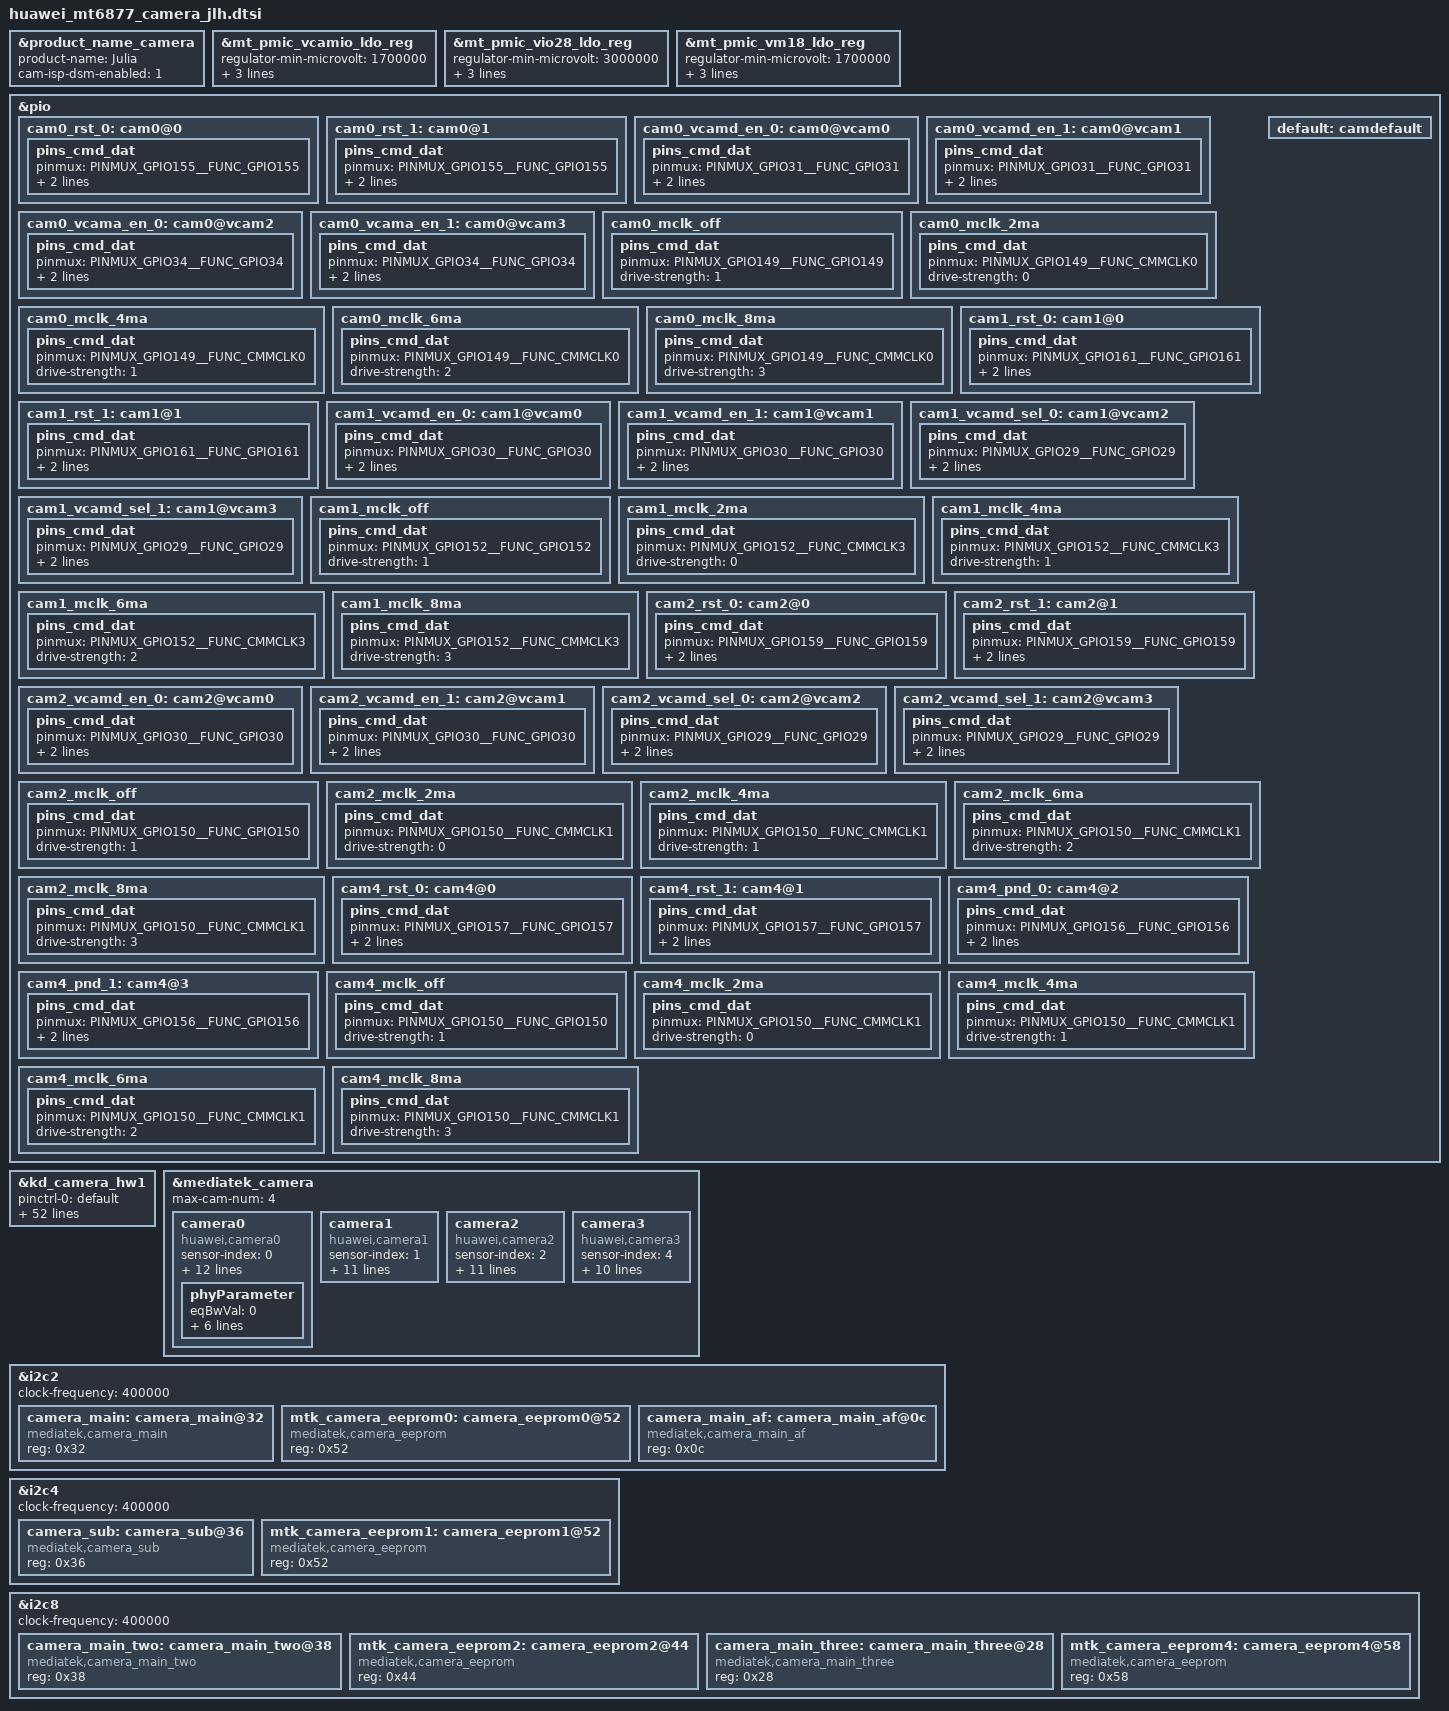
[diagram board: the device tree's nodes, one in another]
/*
 * Copyright (c) 2020 MediaTek Inc.
 *
 * This program is free software; you can redistribute it and/or modify
 * it under the terms of the GNU General Public License version 2 as
 * published by the Free Software Foundation.
 *
 * This program is distributed in the hope that it will be useful,
 * but WITHOUT ANY WARRANTY; without even the implied warranty of
 * MERCHANTABILITY or FITNESS FOR A PARTICULAR PURPOSE.  See the
 * GNU General Public License for more details.
 */

&product_name_camera {
	product-name = "Julia";
	cam-isp-dsm-enabled = <1>;
};

&mt_pmic_vcamio_ldo_reg {
	regulator-min-microvolt = <1700000>;
	regulator-max-microvolt = <1900000>;
	regulator-default-on = <2>; /* 0:skip, 1: off, 2:on */
	regulator-boot-on;
};
&mt_pmic_vio28_ldo_reg {
	regulator-min-microvolt = <3000000>;
	regulator-max-microvolt = <3000000>;
	regulator-default-on = <2>; /* 0:skip, 1: off, 2:on */
	regulator-boot-on;
};
&mt_pmic_vm18_ldo_reg {
	regulator-min-microvolt = <1700000>;
	regulator-max-microvolt = <1900000>;
	regulator-default-on = <2>; /* 0:skip, 1: off, 2:on */
	regulator-boot-on;
};
/* CAMERA GPIO standardization */
&pio {
	/* Main Cam: cam0 GPIOs begin */
	cam0_rst_0: cam0@0 {
		pins_cmd_dat {
			pinmux = <PINMUX_GPIO155__FUNC_GPIO155>;
			slew-rate = <1>;
			output-low;
		};
	};
	cam0_rst_1: cam0@1 {
		pins_cmd_dat {
			pinmux = <PINMUX_GPIO155__FUNC_GPIO155>;
			slew-rate = <1>;
			output-high;
		};
	};

	cam0_vcamd_en_0: cam0@vcam0 {
		pins_cmd_dat {
			pinmux = <PINMUX_GPIO31__FUNC_GPIO31>;
			slew-rate = <1>;
			output-low;
		};
	};
	cam0_vcamd_en_1: cam0@vcam1 {
		pins_cmd_dat {
			pinmux = <PINMUX_GPIO31__FUNC_GPIO31>;
			slew-rate = <1>;
			output-high;
		};
	};

	cam0_vcama_en_0: cam0@vcam2 {
		pins_cmd_dat {
			pinmux = <PINMUX_GPIO34__FUNC_GPIO34>;
			slew-rate = <1>;
			output-low;
		};
	};
	cam0_vcama_en_1: cam0@vcam3 {
		pins_cmd_dat {
			pinmux = <PINMUX_GPIO34__FUNC_GPIO34>;
			slew-rate = <1>;
			output-high;
		};
	};

	cam0_mclk_off: cam0_mclk_off {
		pins_cmd_dat {
			pinmux = <PINMUX_GPIO149__FUNC_GPIO149>;
			drive-strength = <1>;
		};
	};
	cam0_mclk_2ma: cam0_mclk_2ma {
		pins_cmd_dat {
			pinmux = <PINMUX_GPIO149__FUNC_CMMCLK0>;
			drive-strength = <0>;
		};
	};
	cam0_mclk_4ma: cam0_mclk_4ma {
		pins_cmd_dat {
			pinmux = <PINMUX_GPIO149__FUNC_CMMCLK0>;
			drive-strength = <1>;
		};
	};
	cam0_mclk_6ma: cam0_mclk_6ma {
		pins_cmd_dat {
			pinmux = <PINMUX_GPIO149__FUNC_CMMCLK0>;
			drive-strength = <2>;
		};
	};
	cam0_mclk_8ma: cam0_mclk_8ma {
		pins_cmd_dat {
			pinmux = <PINMUX_GPIO149__FUNC_CMMCLK0>;
			drive-strength = <3>;
		};
	};
	/* Main Cam: cam0 GPIOs end */

	/* Sub(front) Cam: cam1 GPIOs begin */
	cam1_rst_0: cam1@0 {
		pins_cmd_dat {
			pinmux = <PINMUX_GPIO161__FUNC_GPIO161>;
			slew-rate = <1>;
			output-low;
		};
	};
	cam1_rst_1: cam1@1 {
		pins_cmd_dat {
			pinmux = <PINMUX_GPIO161__FUNC_GPIO161>;
			slew-rate = <1>;
			output-high;
		};
	};

	cam1_vcamd_en_0: cam1@vcam0 {
		pins_cmd_dat {
			pinmux = <PINMUX_GPIO30__FUNC_GPIO30>;
			slew-rate = <1>;
			output-low;
		};
	};
	cam1_vcamd_en_1: cam1@vcam1 {
		pins_cmd_dat {
			pinmux = <PINMUX_GPIO30__FUNC_GPIO30>;
			slew-rate = <1>;
			output-high;
		};
	};
	/* sel 0, output 1.1V */
	cam1_vcamd_sel_0: cam1@vcam2 {
		pins_cmd_dat {
			pinmux = <PINMUX_GPIO29__FUNC_GPIO29>;
			slew-rate = <1>;
			output-low;
		};
	};
	/* sel 1, output 1.2V */
	cam1_vcamd_sel_1: cam1@vcam3 {
		pins_cmd_dat {
			pinmux = <PINMUX_GPIO29__FUNC_GPIO29>;
			slew-rate = <0>;
			bias-pull-up = <MTK_PUPD_SET_R1R0_00>;
		};
	};

	cam1_mclk_off: cam1_mclk_off {
		pins_cmd_dat {
			pinmux = <PINMUX_GPIO152__FUNC_GPIO152>;
			drive-strength = <1>;
		};
	};
	cam1_mclk_2ma: cam1_mclk_2ma {
		pins_cmd_dat {
			pinmux = <PINMUX_GPIO152__FUNC_CMMCLK3>;
			drive-strength = <0>;
		};
	};
	cam1_mclk_4ma: cam1_mclk_4ma {
		pins_cmd_dat {
			pinmux = <PINMUX_GPIO152__FUNC_CMMCLK3>;
			drive-strength = <1>;
		};
	};
	cam1_mclk_6ma: cam1_mclk_6ma {
		pins_cmd_dat {
			pinmux = <PINMUX_GPIO152__FUNC_CMMCLK3>;
			drive-strength = <2>;
		};
	};
	cam1_mclk_8ma: cam1_mclk_8ma {
		pins_cmd_dat {
			pinmux = <PINMUX_GPIO152__FUNC_CMMCLK3>;
			drive-strength = <3>;
		};
	};
	/* Sub(front) Cam: cam1 GPIOs end */

	/* Main2(wide) Cam: cam2 GPIOs begin */
	cam2_rst_0: cam2@0 {
		pins_cmd_dat {
			pinmux = <PINMUX_GPIO159__FUNC_GPIO159>;
			slew-rate = <1>;
			output-low;
		};
	};
	cam2_rst_1: cam2@1 {
		pins_cmd_dat {
			pinmux = <PINMUX_GPIO159__FUNC_GPIO159>;
			slew-rate = <1>;
			output-high;
		};
	};

	cam2_vcamd_en_0: cam2@vcam0 {
		pins_cmd_dat {
			pinmux = <PINMUX_GPIO30__FUNC_GPIO30>;
			slew-rate = <1>;
			output-low;
		};
	};
	cam2_vcamd_en_1: cam2@vcam1 {
		pins_cmd_dat {
			pinmux = <PINMUX_GPIO30__FUNC_GPIO30>;
			slew-rate = <1>;
			output-high;
		};
	};
	/* sel 0, output 1.1V */
	cam2_vcamd_sel_0: cam2@vcam2 {
		pins_cmd_dat {
			pinmux = <PINMUX_GPIO29__FUNC_GPIO29>;
			slew-rate = <1>;
			output-low;
		};
	};
	/* sel 1, output 1.2V */
	cam2_vcamd_sel_1: cam2@vcam3 {
		pins_cmd_dat {
			pinmux = <PINMUX_GPIO29__FUNC_GPIO29>;
			slew-rate = <0>;
			bias-pull-up = <MTK_PUPD_SET_R1R0_00>;
		};
	};

	cam2_mclk_off: cam2_mclk_off {
		pins_cmd_dat {
			pinmux = <PINMUX_GPIO150__FUNC_GPIO150>;
			drive-strength = <1>;
		};
	};
	cam2_mclk_2ma: cam2_mclk_2ma {
		pins_cmd_dat {
			pinmux = <PINMUX_GPIO150__FUNC_CMMCLK1>;
			drive-strength = <0>;
		};
	};
	cam2_mclk_4ma: cam2_mclk_4ma {
		pins_cmd_dat {
			pinmux = <PINMUX_GPIO150__FUNC_CMMCLK1>;
			drive-strength = <1>;
		};
	};
	cam2_mclk_6ma: cam2_mclk_6ma {
		pins_cmd_dat {
			pinmux = <PINMUX_GPIO150__FUNC_CMMCLK1>;
			drive-strength = <2>;
		};
	};
	cam2_mclk_8ma: cam2_mclk_8ma {
		pins_cmd_dat {
			pinmux = <PINMUX_GPIO150__FUNC_CMMCLK1>;
			drive-strength = <3>;
		};
	};
	/* Main2(wide) Cam: cam2 GPIOs end */

	/* Main3(macro) Cam: cam4 GPIOs begin */
	cam4_rst_0: cam4@0 {
		pins_cmd_dat {
			pinmux = <PINMUX_GPIO157__FUNC_GPIO157>;
			slew-rate = <1>;
			output-low;
		};
	};
	cam4_rst_1: cam4@1 {
		pins_cmd_dat {
			pinmux = <PINMUX_GPIO157__FUNC_GPIO157>;
			slew-rate = <1>;
			output-high;
		};
	};

	cam4_pnd_0: cam4@2 {
		pins_cmd_dat {
			pinmux = <PINMUX_GPIO156__FUNC_GPIO156>;
			slew-rate = <1>;
			output-low;
		};
	};
	cam4_pnd_1: cam4@3 {
		pins_cmd_dat {
			pinmux = <PINMUX_GPIO156__FUNC_GPIO156>;
			slew-rate = <1>;
			output-high;
		};
	};

	cam4_mclk_off: cam4_mclk_off {
		pins_cmd_dat {
			pinmux = <PINMUX_GPIO150__FUNC_GPIO150>;
			drive-strength = <1>;
		};
	};
	cam4_mclk_2ma: cam4_mclk_2ma {
		pins_cmd_dat {
			pinmux = <PINMUX_GPIO150__FUNC_CMMCLK1>;
			drive-strength = <0>;
		};
	};
	cam4_mclk_4ma: cam4_mclk_4ma {
		pins_cmd_dat {
			pinmux = <PINMUX_GPIO150__FUNC_CMMCLK1>;
			drive-strength = <1>;
		};
	};
	cam4_mclk_6ma: cam4_mclk_6ma {
		pins_cmd_dat {
			pinmux = <PINMUX_GPIO150__FUNC_CMMCLK1>;
			drive-strength = <2>;
		};
	};
	cam4_mclk_8ma: cam4_mclk_8ma {
		pins_cmd_dat {
			pinmux = <PINMUX_GPIO150__FUNC_CMMCLK1>;
			drive-strength = <3>;
		};
	};
	/* Main3(macro) Cam: cam4 GPIOs end */

	default: camdefault {
	};
};

&kd_camera_hw1 {
	pinctrl-names = "default",
			/* Main Cam: Cam0 begin */
			"cam0_rst0", "cam0_rst1",
			"cam0_vcamd_en_0", "cam0_vcamd_en_1",
			"cam0_vcama_en_0", "cam0_vcama_en_1",
			"cam0_mclk_off",
			"cam0_mclk_2mA", "cam0_mclk_4mA",
			"cam0_mclk_6mA", "cam0_mclk_8mA",
			/* Main Cam: Cam0 end */

			/* Sub(front) Cam: Cam1 begin */
			"cam1_rst0", "cam1_rst1",
			"cam1_vcamd_en_0", "cam1_vcamd_en_1",
			"cam1_vcamd_sel_0", "cam1_vcamd_sel_1",
			"cam1_mclk_off",
			"cam1_mclk_2mA", "cam1_mclk_4mA",
			"cam1_mclk_6mA", "cam1_mclk_8mA",
			/* Sub(front) Cam: Cam1 end */

			/* Main2(wide) Cam: Cam2 begin */
			"cam2_rst0", "cam2_rst1",
			"cam2_vcamd_en_0", "cam2_vcamd_en_1",
			"cam2_vcamd_sel_0", "cam2_vcamd_sel_1",
			"cam2_mclk_off",
			"cam2_mclk_2mA", "cam2_mclk_4mA",
			"cam2_mclk_6mA", "cam2_mclk_8mA",
			/* Main2(wide) Cam: cam2 end */

			/* Main3(macro) Cam: cam4 begin */
			"cam4_rst0", "cam4_rst1",
			"cam4_pnd0", "cam4_pnd1",
			"cam4_mclk_off",
			"cam4_mclk_2mA", "cam4_mclk_4mA",
			"cam4_mclk_6mA", "cam4_mclk_8mA";
			/* Main3(macro) Cam: cam4 end */

	pinctrl-0 = <&default>;
	/* Main Cam: Cam0 begin */
	pinctrl-1 = <&cam0_rst_0>;
	pinctrl-2 = <&cam0_rst_1>;
	pinctrl-3 = <&cam0_vcamd_en_0>;
	pinctrl-4 = <&cam0_vcamd_en_1>;
	pinctrl-5 = <&cam0_vcama_en_0>;
	pinctrl-6 = <&cam0_vcama_en_1>;
	pinctrl-7 = <&cam0_mclk_off>;
	pinctrl-8 = <&cam0_mclk_2ma>;
	pinctrl-9 = <&cam0_mclk_4ma>;
	pinctrl-10 = <&cam0_mclk_6ma>;
	pinctrl-11 = <&cam0_mclk_8ma>;
	/* Sub(front) Cam: Cam1 begin */
	pinctrl-12 = <&cam1_rst_0>;
	pinctrl-13 = <&cam1_rst_1>;
	pinctrl-14 = <&cam1_vcamd_en_0>;
	pinctrl-15 = <&cam1_vcamd_en_1>;
	pinctrl-16 = <&cam1_vcamd_sel_0>;
	pinctrl-17 = <&cam1_vcamd_sel_1>;
	pinctrl-18 = <&cam1_mclk_off>;
	pinctrl-19 = <&cam1_mclk_2ma>;
	pinctrl-20 = <&cam1_mclk_4ma>;
	pinctrl-21 = <&cam1_mclk_6ma>;
	pinctrl-22 = <&cam1_mclk_8ma>;
	/* Main2(wide) Cam: Cam2 begin */
	pinctrl-23 = <&cam2_rst_0>;
	pinctrl-24 = <&cam2_rst_1>;
	pinctrl-25 = <&cam2_vcamd_en_0>;
	pinctrl-26 = <&cam2_vcamd_en_1>;
	pinctrl-27 = <&cam2_vcamd_sel_0>;
	pinctrl-28 = <&cam2_vcamd_sel_1>;
	pinctrl-29 = <&cam2_mclk_off>;
	pinctrl-30 = <&cam2_mclk_2ma>;
	pinctrl-31 = <&cam2_mclk_4ma>;
	pinctrl-32 = <&cam2_mclk_6ma>;
	pinctrl-33 = <&cam2_mclk_8ma>;
	/* Main3(micro) Cam: Cam3 begin */
	pinctrl-34 = <&cam4_rst_0>;
	pinctrl-35 = <&cam4_rst_1>;
	pinctrl-36 = <&cam4_pnd_0>;
	pinctrl-37 = <&cam4_pnd_1>;
	pinctrl-38 = <&cam4_mclk_off>;
	pinctrl-39 = <&cam4_mclk_2ma>;
	pinctrl-40 = <&cam4_mclk_4ma>;
	pinctrl-41 = <&cam4_mclk_6ma>;
	pinctrl-42 = <&cam4_mclk_8ma>;

	cam0_vcamio-supply = <&mt_pmic_vcamio_ldo_reg>;
	cam0_vcama-supply  = <&mt_pmic_vtp_ldo_reg>;
	cam0_vcamd-supply  = <&mt6315_3_vbuck3>;

	cam1_vcamio-supply = <&mt_pmic_vcamio_ldo_reg>;
	cam1_vcama-supply  = <&mt_pmic_vmch_ldo_reg>;

	cam2_vcamio-supply = <&mt_pmic_vcamio_ldo_reg>;
	cam2_vcama-supply  = <&mt_pmic_vmch_ldo_reg>;

/* main3 macro */
	cam4_vcamio-supply = <&mt_pmic_vcamio_ldo_reg>;
	cam4_vcama-supply  = <&mt_pmic_vmch_ldo_reg>;

	status = "okay";

	fastmode_regulators = "cam0_vcamd";
};
/* CAMERA GPIO end */
&mediatek_camera {
	max-cam-num = "4";

	camera0 {
		compatible    = "huawei,camera0";
		sensor-index  = "0";
		mclk-index    = "0";
		csi-port      = "3";
		csi-dir       = "0";
		bit-order     = "0";
		orientation   = "90";
		sensor-hfov   = "67";
		sensor-vfov   = "49";

		i2c-dev-index = <0>;  // IMGSENSOR_I2C_DEV_0
		pin-type      =
				"mclk",
				"avdd",
				"avdd_en",
				"dvdd_en",
				"dvdd",
				"dovdd",
				"rst";
		pin-id       = <0 1 2 2 1 1 2>;
		phyType      = "1";
		phyParameter {
			eqBwVal = "0";
			eqIsVal = "1";
			eqLatchEnVal = "1";
			eqDg0EnVal = "1";
			eqDg1EnVal = "1";
			eqSr0Val = "3";
			eqSr1Val = "3";
		};
	};

	camera1 {
		compatible    = "huawei,camera1";
		sensor-index  = "1";
		mclk-index    = "3";
		csi-port      = "2";
		csi-dir       = "1";
		bit-order     = "0";
		orientation   = "270";
		sensor-hfov   = "63";
		sensor-vfov   = "40";

		i2c-dev-index = <1>;  // IMGSENSOR_I2C_DEV_1
		pin-type      =
				"mclk",
				"avdd",
				"dvdd_en",
				"dvdd_sel",
				"dovdd",
				"rst";
		pin-id       = <0 1 2 2 1 2>;
	};

	camera2 {
		compatible    = "huawei,camera2";
		sensor-index  = "2";
		mclk-index    = "1";
		csi-port      = "1";
		csi-dir       = "0";
		bit-order     = "0";
		orientation   = "90";
		sensor-hfov   = "75";
		sensor-vfov   = "60";

		i2c-dev-index = <2>;  // IMGSENSOR_I2C_DEV_2
		pin-type      =
				"mclk",
				"avdd",
				"dvdd_en",
				"dvdd_sel",
				"dovdd",
				"rst";
		pin-id       = <0 1 2 2 1 2>;
	};

	camera3 {
		compatible    = "huawei,camera3";
		sensor-index  = "4";
		mclk-index    = "1";
		csi-port      = "0";
		csi-dir       = "0";
		bit-order     = "0";
		orientation   = "90";
		sensor-hfov   = "75";
		sensor-vfov   = "60";

		i2c-dev-index = <4>;  // IMGSENSOR_I2C_DEV_4
		pin-type      =
				"mclk",
				"avdd",
				"dovdd",
				"pwdn",
				"rst";
		pin-id       = <0 1 1 2 2>;
	};
};
/* CAMERA */
&i2c2 {
	clock-frequency = <400000>;
	camera_main:camera_main@32 {
		compatible = "mediatek,camera_main";
		reg = <0x32>;
		status = "okay";
	};
	mtk_camera_eeprom0:camera_eeprom0@52 {
		compatible = "mediatek,camera_eeprom";
		reg = <0x52>;
		status = "okay";
	};
	camera_main_af:camera_main_af@0c {
		compatible = "mediatek,camera_main_af";
		reg = <0x0c>;
		status = "okay";
	};
};

&i2c4 {
	clock-frequency = <400000>;
	camera_sub:camera_sub@36 {
		compatible = "mediatek,camera_sub";
		reg = <0x36>;
		status = "okay";
	};
	mtk_camera_eeprom1:camera_eeprom1@52 {
		compatible = "mediatek,camera_eeprom";
		reg = <0x52>;
		status = "okay";
	};
};

&i2c8 {
	clock-frequency = <400000>;
	/* wide */
	camera_main_two:camera_main_two@38 {
		compatible = "mediatek,camera_main_two";
		reg = <0x38>;
		status = "okay";
	};
	mtk_camera_eeprom2:camera_eeprom2@44 {
		compatible = "mediatek,camera_eeprom";
		reg = <0x44>;
		status = "okay";
	};
	/* macro */
	camera_main_three:camera_main_three@28 {
		compatible = "mediatek,camera_main_three";
		reg = <0x28>;
		status = "okay";
	};
	mtk_camera_eeprom4:camera_eeprom4@58 {
		compatible = "mediatek,camera_eeprom";
		reg = <0x58>;
		status = "okay";
	};
};

/* CAMERA end */
